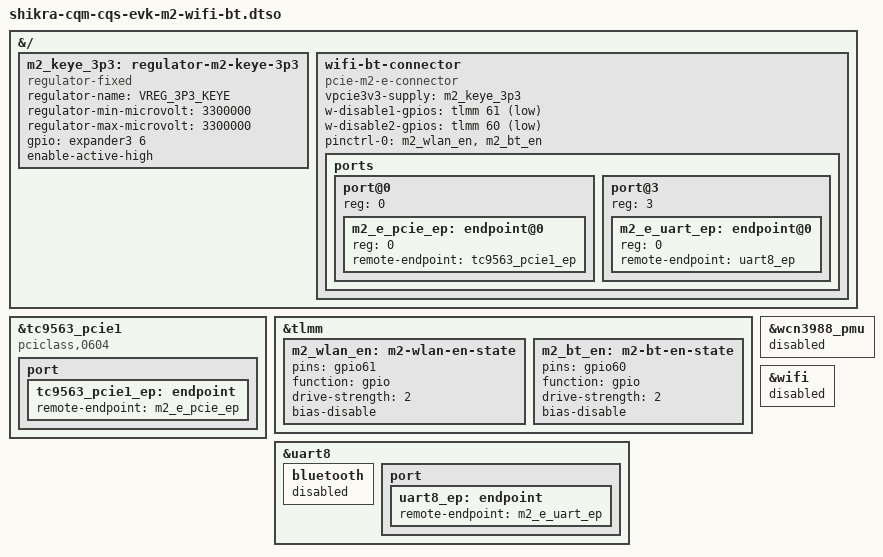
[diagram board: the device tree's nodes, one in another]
// SPDX-License-Identifier: BSD-3-Clause
/*
 * Copyright (c) Qualcomm Technologies, Inc. and/or its subsidiaries.
 */

/dts-v1/;
/plugin/;

#include <dt-bindings/gpio/gpio.h>

/*
 * M.2 Key-E WiFi/BT card behind the QPS615 (TC9563) PCIe switch. The M.2 UART
 * shares UART8 with the on-board WCN3988 BT, so the two are mutually exclusive.
 */

&{/} {
	m2_keye_3p3: regulator-m2-keye-3p3 {
		compatible = "regulator-fixed";
		regulator-name = "VREG_3P3_KEYE";
		regulator-min-microvolt = <3300000>;
		regulator-max-microvolt = <3300000>;
		gpio = <&expander3 6 GPIO_ACTIVE_HIGH>;
		enable-active-high;
	};

	wifi-bt-connector {
		compatible = "pcie-m2-e-connector";

		vpcie3v3-supply = <&m2_keye_3p3>;
		w-disable1-gpios = <&tlmm 61 GPIO_ACTIVE_LOW>;
		w-disable2-gpios = <&tlmm 60 GPIO_ACTIVE_LOW>;

		pinctrl-0 = <&m2_wlan_en>, <&m2_bt_en>;
		pinctrl-names = "default";

		ports {
			#address-cells = <1>;
			#size-cells = <0>;

			port@0 {
				reg = <0>;
				#address-cells = <1>;
				#size-cells = <0>;

				m2_e_pcie_ep: endpoint@0 {
					reg = <0>;
					remote-endpoint = <&tc9563_pcie1_ep>;
				};
			};

			port@3 {
				reg = <3>;
				#address-cells = <1>;
				#size-cells = <0>;

				m2_e_uart_ep: endpoint@0 {
					reg = <0>;
					remote-endpoint = <&uart8_ep>;
				};
			};
		};
	};
};

&tc9563_pcie1 {
	compatible = "pciclass,0604";

	port {
		tc9563_pcie1_ep: endpoint {
			remote-endpoint = <&m2_e_pcie_ep>;
		};
	};
};

&tlmm {
	m2_wlan_en: m2-wlan-en-state {
		pins = "gpio61";
		function = "gpio";
		drive-strength = <2>;
		bias-disable;
	};

	m2_bt_en: m2-bt-en-state {
		pins = "gpio60";
		function = "gpio";
		drive-strength = <2>;
		bias-disable;
	};
};

&uart8 {
	bluetooth {
		status = "disabled";
	};

	port {
		uart8_ep: endpoint {
			remote-endpoint = <&m2_e_uart_ep>;
		};
	};
};

&wcn3988_pmu {
	status = "disabled";
};

&wifi {
	status = "disabled";
};
